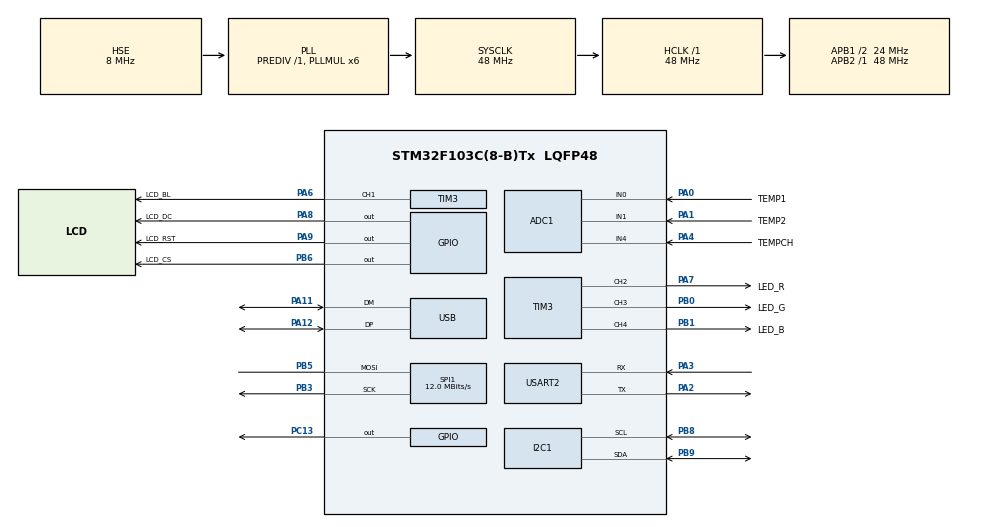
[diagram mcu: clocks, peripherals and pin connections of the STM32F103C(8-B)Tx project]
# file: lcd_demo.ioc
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ADC1.Channel-1\#ChannelRegularConversion=ADC_CHANNEL_0
ADC1.ContinuousConvMode=DISABLE
ADC1.NbrOfConversionFlag=1
ADC1.Rank-1\#ChannelRegularConversion=1
ADC1.SamplingTime-1\#ChannelRegularConversion=ADC_SAMPLETIME_1CYCLE_5
ADC1.master=1
FREERTOS.Tasks01=vMainTask,32,128,StartDefaultTask,Default,NULL,Dynamic,NULL,NULL;vDisplayTask,8,128,StartTask02,Default,NULL,Dynamic,NULL,NULL;vWifiTask,8,128,StartTask03,Default,NULL,Dynamic,NULL,NULL
FREERTOS.configMINIMAL_STACK_SIZE=64
FREERTOS.configUSE_NEWLIB_REENTRANT=1
Mcu.Family=STM32F1
Mcu.Name=STM32F103C(8-B)Tx
Mcu.Package=LQFP48
NVIC.PriorityGroup=NVIC_PRIORITYGROUP_4
PA0-WKUP.GPIO_Label=TEMP1
PA0-WKUP.Signal=ADCx_IN0
PA1.GPIO_Label=TEMP2
PA1.Signal=ADCx_IN1
PA11.Mode=Device
PA11.Signal=USB_DM
PA12.Mode=Device
PA12.Signal=USB_DP
PA13.Mode=Serial_Wire
PA13.Signal=SYS_JTMS-SWDIO
PA14.Mode=Serial_Wire
PA14.Signal=SYS_JTCK-SWCLK
PA2.Mode=Asynchronous
PA2.Signal=USART2_TX
PA3.Mode=Asynchronous
PA3.Signal=USART2_RX
PA4.GPIO_Label=TEMPCH
PA4.Signal=ADCx_IN4
PA6.GPIO_Label=LCD_BL
PA6.Signal=S_TIM3_CH1
PA7.GPIO_Label=LED_R
PA7.Signal=S_TIM3_CH2
PA8.GPIO_Label=LCD_DC
PA8.Signal=GPIO_Output
PA9.GPIO_Label=LCD_RST
PA9.Signal=GPIO_Output
PB0.GPIO_Label=LED_G
PB0.Signal=S_TIM3_CH3
PB1.GPIO_Label=LED_B
PB1.Signal=S_TIM3_CH4
PB3.Mode=Simplex_Bidirectional_Master
PB3.Signal=SPI1_SCK
PB5.Mode=Simplex_Bidirectional_Master
PB5.Signal=SPI1_MOSI
PB6.GPIO_Label=LCD_CS
PB6.Signal=GPIO_Output
PB8.Mode=I2C
PB8.Signal=I2C1_SCL
PB9.Mode=I2C
PB9.Signal=I2C1_SDA
PC13-TAMPER-RTC.Signal=GPIO_Output
PD0-OSC_IN.Mode=HSE-External-Oscillator
PD0-OSC_IN.Signal=RCC_OSC_IN
PD1-OSC_OUT.Mode=HSE-External-Oscillator
PD1-OSC_OUT.Signal=RCC_OSC_OUT
ProjectManager.HeapSize=0x200
ProjectManager.StackSize=0x400
ProjectManager.TargetToolchain=STM32CubeIDE
RCC.ADCPresc=RCC_ADCPCLK2_DIV4
RCC.AHBFreq_Value=48000000
RCC.APB1CLKDivider=RCC_HCLK_DIV2
RCC.APB1Freq_Value=24000000
RCC.APB1TimFreq_Value=48000000
RCC.APB2Freq_Value=48000000
RCC.APB2TimFreq_Value=48000000
RCC.HCLKFreq_Value=48000000
RCC.PLLMUL=RCC_PLL_MUL6
RCC.PLLSourceVirtual=RCC_PLLSOURCE_HSE
RCC.SYSCLKFreq_VALUE=48000000
RCC.SYSCLKSource=RCC_SYSCLKSOURCE_PLLCLK
RCC.USBFreq_Value=48000000
SH.ADCx_IN0.0=ADC1_IN0,IN0
SH.ADCx_IN1.0=ADC1_IN1,IN1
SH.ADCx_IN4.0=ADC1_IN4,IN4
SH.S_TIM3_CH1.0=TIM3_CH1,PWM Generation1 CH1
SH.S_TIM3_CH2.0=TIM3_CH2,PWM Generation2 CH2
SH.S_TIM3_CH3.0=TIM3_CH3,PWM Generation3 CH3
SH.S_TIM3_CH4.0=TIM3_CH4,PWM Generation4 CH4
SPI1.BaudRatePrescaler=SPI_BAUDRATEPRESCALER_4
SPI1.CalculateBaudRate=12.0 MBits/s
SPI1.Direction=SPI_DIRECTION_1LINE
SPI1.Mode=SPI_MODE_MASTER
SPI1.VirtualType=VM_MASTER
TIM3.Channel-PWM\ Generation1\ CH1=TIM_CHANNEL_1
TIM3.Channel-PWM\ Generation2\ CH2=TIM_CHANNEL_2
TIM3.Channel-PWM\ Generation3\ CH3=TIM_CHANNEL_3
TIM3.Channel-PWM\ Generation4\ CH4=TIM_CHANNEL_4
USART2.VirtualMode=VM_ASYNC
VP_FREERTOS_VS_CMSIS_V2.Mode=CMSIS_V2
board=custom

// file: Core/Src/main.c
/* USER CODE BEGIN Header */
/**
 ******************************************************************************
 * @file           : main.c
 * @brief          : Main program body
 ******************************************************************************
 * @attention
 *
 * <h2><centre>&copy; Copyright (c) 2020 STMicroelectronics.
 * All rights reserved.</centre></h2>
 *
 * This software component is licensed by ST under BSD 3-Clause license,
 * the "License"; You may not use this file except in compliance with the
 * License. You may obtain a copy of the License at:
 *                        opensource.org/licenses/BSD-3-Clause
 *
 ******************************************************************************
 */
/* USER CODE END Header */
#include "main.h"
#include "cmsis_os.h"

/* USER CODE BEGIN Includes */
#include "GUI_Paint.h"
#include "fonts.h"
#include "image.h"
#include "LCD_Test.h"
/* USER CODE END Includes */

ADC_HandleTypeDef hadc1;

I2C_HandleTypeDef hi2c1;

SPI_HandleTypeDef hspi1;

TIM_HandleTypeDef htim3;

UART_HandleTypeDef huart2;

PCD_HandleTypeDef hpcd_USB_FS;

/* Definitions for vMainTask */
osThreadId_t vMainTaskHandle;
const osThreadAttr_t vMainTask_attributes = { .name = "vMainTask", .stack_size =
		128 * 4, .priority = (osPriority_t) osPriorityAboveNormal, };
/* Definitions for vDisplayTask */
osThreadId_t vDisplayTaskHandle;
const osThreadAttr_t vDisplayTask_attributes = { .name = "vDisplayTask",
		.stack_size = 128 * 4, .priority = (osPriority_t) osPriorityLow, };
/* Definitions for vWifiTask */
osThreadId_t vWifiTaskHandle;
const osThreadAttr_t vWifiTask_attributes = { .name = "vWifiTask", .stack_size =
		128 * 4, .priority = (osPriority_t) osPriorityLow, };

void SystemClock_Config(void);
static void MX_GPIO_Init(void);
static void MX_SPI1_Init(void);
static void MX_TIM3_Init(void);
static void MX_USART2_UART_Init(void);
static void MX_USB_PCD_Init(void);
static void MX_ADC1_Init(void);
static void MX_I2C1_Init(void);
void StartDefaultTask(void *argument);
void StartTask02(void *argument);
void StartTask03(void *argument);

int main(void) {

	/* MCU Configuration--------------------------------------------------------*/

	/* Reset of all peripherals, Initializes the Flash interface and the Systick. */
	HAL_Init();

	/* Configure the system clock */
	SystemClock_Config();

	/* Initialize all configured peripherals */
	MX_GPIO_Init();
	MX_SPI1_Init();
	MX_TIM3_Init();
	MX_USART2_UART_Init();
	MX_USB_PCD_Init();
	MX_ADC1_Init();
	MX_I2C1_Init();
	/* USER CODE BEGIN 2 */
	LCD_1in54_test();

	/* USER CODE END 2 */

	/* Init scheduler */
	osKernelInitialize();

	/* Create the thread(s) */
	/* creation of vMainTask */
	vMainTaskHandle = osThreadNew(StartDefaultTask, NULL,
			&vMainTask_attributes);

	/* creation of vDisplayTask */
	vDisplayTaskHandle = osThreadNew(StartTask02, NULL,
			&vDisplayTask_attributes);

	/* creation of vWifiTask */
	vWifiTaskHandle = osThreadNew(StartTask03, NULL, &vWifiTask_attributes);

	/* Start scheduler */
	osKernelStart();

	/* We should never get here as control is now taken by the scheduler */
	/* Infinite loop */
	/* USER CODE BEGIN WHILE */
	printf("Error starting scheduler\r\n");
	while (1) {
		/* USER CODE END WHILE */

	}
}

void SystemClock_Config(void) {
	RCC_OscInitTypeDef RCC_OscInitStruct = { 0 };
	RCC_ClkInitTypeDef RCC_ClkInitStruct = { 0 };
	RCC_PeriphCLKInitTypeDef PeriphClkInit = { 0 };

	/** Initializes the RCC Oscillators according to the specified parameters
	 * in the RCC_OscInitTypeDef structure.
	 */
	RCC_OscInitStruct.OscillatorType = RCC_OSCILLATORTYPE_HSE;
	RCC_OscInitStruct.HSEState = RCC_HSE_ON;
	RCC_OscInitStruct.HSEPredivValue = RCC_HSE_PREDIV_DIV1;
	RCC_OscInitStruct.HSIState = RCC_HSI_ON;
	RCC_OscInitStruct.PLL.PLLState = RCC_PLL_ON;
	RCC_OscInitStruct.PLL.PLLSource = RCC_PLLSOURCE_HSE;
	RCC_OscInitStruct.PLL.PLLMUL = RCC_PLL_MUL6;
	if (HAL_RCC_OscConfig(&RCC_OscInitStruct) != HAL_OK) {
		Error_Handler();
	}

	/** Initializes the CPU, AHB and APB buses clocks
	 */
	RCC_ClkInitStruct.ClockType = RCC_CLOCKTYPE_HCLK | RCC_CLOCKTYPE_SYSCLK
			| RCC_CLOCKTYPE_PCLK1 | RCC_CLOCKTYPE_PCLK2;
	RCC_ClkInitStruct.SYSCLKSource = RCC_SYSCLKSOURCE_PLLCLK;
	RCC_ClkInitStruct.AHBCLKDivider = RCC_SYSCLK_DIV1;
	RCC_ClkInitStruct.APB1CLKDivider = RCC_HCLK_DIV2;
	RCC_ClkInitStruct.APB2CLKDivider = RCC_HCLK_DIV1;

	if (HAL_RCC_ClockConfig(&RCC_ClkInitStruct, FLASH_LATENCY_1) != HAL_OK) {
		Error_Handler();
	}
	PeriphClkInit.PeriphClockSelection = RCC_PERIPHCLK_ADC | RCC_PERIPHCLK_USB;
	PeriphClkInit.AdcClockSelection = RCC_ADCPCLK2_DIV4;
	PeriphClkInit.UsbClockSelection = RCC_USBCLKSOURCE_PLL;
	if (HAL_RCCEx_PeriphCLKConfig(&PeriphClkInit) != HAL_OK) {
		Error_Handler();
	}
}

/**
 * @brief ADC1 Initialisation Function
 * @param None
 * @retval None
 */
static void MX_ADC1_Init(void) {

	ADC_ChannelConfTypeDef sConfig = { 0 };

	/** Common config
	 */
	hadc1.Instance = ADC1;
	hadc1.Init.ScanConvMode = ADC_SCAN_DISABLE;
	hadc1.Init.ContinuousConvMode = DISABLE;
	hadc1.Init.DiscontinuousConvMode = DISABLE;
	hadc1.Init.ExternalTrigConv = ADC_SOFTWARE_START;
	hadc1.Init.DataAlign = ADC_DATAALIGN_RIGHT;
	hadc1.Init.NbrOfConversion = 1;
	if (HAL_ADC_Init(&hadc1) != HAL_OK) {
		Error_Handler();
	}

	/** Configure Regular Channel
	 */
	sConfig.Channel = ADC_CHANNEL_0;
	sConfig.Rank = ADC_REGULAR_RANK_1;
	sConfig.SamplingTime = ADC_SAMPLETIME_1CYCLE_5;
	if (HAL_ADC_ConfigChannel(&hadc1, &sConfig) != HAL_OK) {
		Error_Handler();
	}

}

/**
 * @brief I2C1 Initialisation Function
 * @param None
 * @retval None
 */
static void MX_I2C1_Init(void) {

	hi2c1.Instance = I2C1;
	hi2c1.Init.ClockSpeed = 100000;
	hi2c1.Init.DutyCycle = I2C_DUTYCYCLE_2;
	hi2c1.Init.OwnAddress1 = 0;
	hi2c1.Init.AddressingMode = I2C_ADDRESSINGMODE_7BIT;
	hi2c1.Init.DualAddressMode = I2C_DUALADDRESS_DISABLE;
	hi2c1.Init.OwnAddress2 = 0;
	hi2c1.Init.GeneralCallMode = I2C_GENERALCALL_DISABLE;
	hi2c1.Init.NoStretchMode = I2C_NOSTRETCH_DISABLE;
	if (HAL_I2C_Init(&hi2c1) != HAL_OK) {
		Error_Handler();
	}

}

/**
 * @brief SPI1 Initialisation Function
 * @param None
 * @retval None
 */
static void MX_SPI1_Init(void) {

	/* SPI1 parameter configuration*/
	hspi1.Instance = SPI1;
	hspi1.Init.Mode = SPI_MODE_MASTER;
	hspi1.Init.Direction = SPI_DIRECTION_1LINE;
	hspi1.Init.DataSize = SPI_DATASIZE_8BIT;
	hspi1.Init.CLKPolarity = SPI_POLARITY_LOW;
	hspi1.Init.CLKPhase = SPI_PHASE_1EDGE;
	hspi1.Init.NSS = SPI_NSS_SOFT;
	hspi1.Init.BaudRatePrescaler = SPI_BAUDRATEPRESCALER_4;
	hspi1.Init.FirstBit = SPI_FIRSTBIT_MSB;
	hspi1.Init.TIMode = SPI_TIMODE_DISABLE;
	hspi1.Init.CRCCalculation = SPI_CRCCALCULATION_DISABLE;
	hspi1.Init.CRCPolynomial = 10;
	if (HAL_SPI_Init(&hspi1) != HAL_OK) {
		Error_Handler();
	}

}

/**
 * @brief TIM3 Initialisation Function
 * @param None
 * @retval None
 */
static void MX_TIM3_Init(void) {

	/* USER CODE BEGIN TIM3_Init 0 */
//
	/* USER CODE END TIM3_Init 0 */

	TIM_MasterConfigTypeDef sMasterConfig = { 0 };
	TIM_OC_InitTypeDef sConfigOC = { 0 };

	/* USER CODE BEGIN TIM3_Init 1 */
//
	/* USER CODE END TIM3_Init 1 */
	htim3.Instance = TIM3;
	htim3.Init.Prescaler = 0;
	htim3.Init.CounterMode = TIM_COUNTERMODE_UP;
	htim3.Init.Period = 65535;
	htim3.Init.ClockDivision = TIM_CLOCKDIVISION_DIV1;
	htim3.Init.AutoReloadPreload = TIM_AUTORELOAD_PRELOAD_DISABLE;
	if (HAL_TIM_PWM_Init(&htim3) != HAL_OK) {
		Error_Handler();
	}
	sMasterConfig.MasterOutputTrigger = TIM_TRGO_RESET;
	sMasterConfig.MasterSlaveMode = TIM_MASTERSLAVEMODE_DISABLE;
	if (HAL_TIMEx_MasterConfigSynchronization(&htim3, &sMasterConfig)
			!= HAL_OK) {
		Error_Handler();
	}
	sConfigOC.OCMode = TIM_OCMODE_PWM1;
	sConfigOC.Pulse = 0;
	sConfigOC.OCPolarity = TIM_OCPOLARITY_HIGH;
	sConfigOC.OCFastMode = TIM_OCFAST_DISABLE;
	if (HAL_TIM_PWM_ConfigChannel(&htim3, &sConfigOC, TIM_CHANNEL_1)
			!= HAL_OK) {
		Error_Handler();
	}
	if (HAL_TIM_PWM_ConfigChannel(&htim3, &sConfigOC, TIM_CHANNEL_2)
			!= HAL_OK) {
		Error_Handler();
	}
	if (HAL_TIM_PWM_ConfigChannel(&htim3, &sConfigOC, TIM_CHANNEL_3)
			!= HAL_OK) {
		Error_Handler();
	}
	if (HAL_TIM_PWM_ConfigChannel(&htim3, &sConfigOC, TIM_CHANNEL_4)
			!= HAL_OK) {
		Error_Handler();
	}
	/* USER CODE BEGIN TIM3_Init 2 */
//
	/* USER CODE END TIM3_Init 2 */
	HAL_TIM_MspPostInit(&htim3);

}

/**
 * @brief USART2 Initialisation Function
 * @param None
 * @retval None
 */
static void MX_USART2_UART_Init(void) {

	/* USER CODE BEGIN USART2_Init 0 */
//
	/* USER CODE END USART2_Init 0 */

	/* USER CODE BEGIN USART2_Init 1 */
//
	/* USER CODE END USART2_Init 1 */
	huart2.Instance = USART2;
	huart2.Init.BaudRate = 115200;
	huart2.Init.WordLength = UART_WORDLENGTH_8B;
	huart2.Init.StopBits = UART_STOPBITS_1;
	huart2.Init.Parity = UART_PARITY_NONE;
	huart2.Init.Mode = UART_MODE_TX_RX;
	huart2.Init.HwFlowCtl = UART_HWCONTROL_NONE;
	huart2.Init.OverSampling = UART_OVERSAMPLING_16;
	if (HAL_UART_Init(&huart2) != HAL_OK) {
		Error_Handler();
	}
	/* USER CODE BEGIN USART2_Init 2 */
//
	/* USER CODE END USART2_Init 2 */

}

/**
 * @brief USB Initialisation Function
 * @param None
 * @retval None
 */
static void MX_USB_PCD_Init(void) {

	hpcd_USB_FS.Instance = USB;
	hpcd_USB_FS.Init.dev_endpoints = 8;
	hpcd_USB_FS.Init.speed = PCD_SPEED_FULL;
	hpcd_USB_FS.Init.low_power_enable = DISABLE;
	hpcd_USB_FS.Init.lpm_enable = DISABLE;
	hpcd_USB_FS.Init.battery_charging_enable = DISABLE;
	if (HAL_PCD_Init(&hpcd_USB_FS) != HAL_OK) {
		Error_Handler();
	}

}

/**
 * @brief GPIO Initialisation Function
 * @param None
 * @retval None
 */
static void MX_GPIO_Init(void) {
	GPIO_InitTypeDef GPIO_InitStruct = { 0 };

	/* GPIO Ports Clock Enable */
	__HAL_RCC_GPIOC_CLK_ENABLE();
	__HAL_RCC_GPIOD_CLK_ENABLE();
	__HAL_RCC_GPIOA_CLK_ENABLE();
	__HAL_RCC_GPIOB_CLK_ENABLE();

	/*Configure GPIO pin Output Level */
	HAL_GPIO_WritePin(GPIOC, GPIO_PIN_13, GPIO_PIN_RESET);

	/*Configure GPIO pin Output Level */
	HAL_GPIO_WritePin(GPIOA, LCD_DC_Pin | LCD_RST_Pin, GPIO_PIN_RESET);

	/*Configure GPIO pin Output Level */
	HAL_GPIO_WritePin(LCD_CS_GPIO_Port, LCD_CS_Pin, GPIO_PIN_RESET);

	/*Configure GPIO pin : PC13 */
	GPIO_InitStruct.Pin = GPIO_PIN_13;
	GPIO_InitStruct.Mode = GPIO_MODE_OUTPUT_PP;
	GPIO_InitStruct.Pull = GPIO_NOPULL;
	GPIO_InitStruct.Speed = GPIO_SPEED_FREQ_LOW;
	HAL_GPIO_Init(GPIOC, &GPIO_InitStruct);

	/*Configure GPIO pins : LCD_DC_Pin LCD_RST_Pin */
	GPIO_InitStruct.Pin = LCD_DC_Pin | LCD_RST_Pin;
	GPIO_InitStruct.Mode = GPIO_MODE_OUTPUT_PP;
	GPIO_InitStruct.Pull = GPIO_NOPULL;
	GPIO_InitStruct.Speed = GPIO_SPEED_FREQ_LOW;
	HAL_GPIO_Init(GPIOA, &GPIO_InitStruct);

	/*Configure GPIO pin : LCD_CS_Pin */
	GPIO_InitStruct.Pin = LCD_CS_Pin;
	GPIO_InitStruct.Mode = GPIO_MODE_OUTPUT_PP;
	GPIO_InitStruct.Pull = GPIO_NOPULL;
	GPIO_InitStruct.Speed = GPIO_SPEED_FREQ_LOW;
	HAL_GPIO_Init(LCD_CS_GPIO_Port, &GPIO_InitStruct);

}

void StartDefaultTask(void *argument) {
	/* USER CODE BEGIN 5 */
	/* Infinite loop */
	while (1) {
		HAL_GPIO_TogglePin(GPIOC, GPIO_PIN_13);
		osDelay(500);
	}
	/* USER CODE END 5 */
}

void StartTask02(void *argument) {
	while (1) {
		osDelay(1);
	}
}

void StartTask03(void *argument) {
	while (1) {
		osDelay(1);
	}
}

void Error_Handler(void) {
	/* USER CODE BEGIN Error_Handler_Debug */
	/* User can add his own implementation to report the HAL error return state */
	printf("HAL Error\r\n");
	while (1)
		;
	/* USER CODE END Error_Handler_Debug */
}
